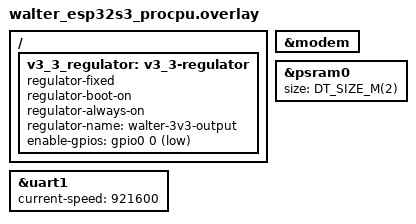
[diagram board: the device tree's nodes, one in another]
/ {
	v3_3_regulator: v3_3-regulator {
		regulator-boot-on;
		regulator-always-on;
		compatible = "regulator-fixed";
		regulator-name = "walter-3v3-output";
		enable-gpios = <&gpio0 0 GPIO_ACTIVE_LOW>;
	};
};

&uart1 {
	current-speed = <921600>;
};

&modem {
	/delete-property/ mdm-wake-gpios;
};

&psram0 {
	size = <DT_SIZE_M(2)>;
};
